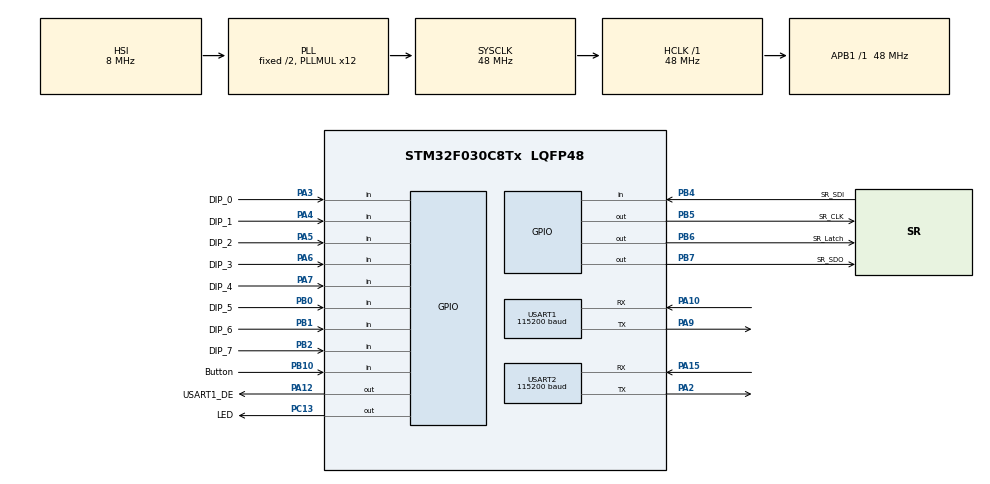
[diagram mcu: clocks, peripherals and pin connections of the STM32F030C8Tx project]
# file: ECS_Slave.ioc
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Mcu.Family=STM32F0
Mcu.Name=STM32F030C8Tx
Mcu.Package=LQFP48
NVIC.USART1_IRQn=true\:0\:0\:false\:false\:true\:true\:true\:true
PA10.Mode=Asynchronous
PA10.Signal=USART1_RX
PA12.GPIO_Label=USART1_DE
PA12.Signal=GPIO_Output
PA13.Mode=Serial_Wire
PA13.Signal=SYS_SWDIO
PA14.Mode=Serial_Wire
PA14.Signal=SYS_SWCLK
PA15.GPIO_PuPd=GPIO_PULLUP
PA15.Mode=Asynchronous
PA15.Signal=USART2_RX
PA2.Mode=Asynchronous
PA2.Signal=USART2_TX
PA3.GPIO_Label=DIP_0
PA3.GPIO_Mode=GPIO_MODE_INPUT
PA3.GPIO_PuPd=GPIO_PULLUP
PA3.Signal=GPIO_Input
PA4.GPIO_Label=DIP_1
PA4.GPIO_Mode=GPIO_MODE_INPUT
PA4.GPIO_PuPd=GPIO_PULLUP
PA4.Signal=GPIO_Input
PA5.GPIO_Label=DIP_2
PA5.GPIO_Mode=GPIO_MODE_INPUT
PA5.GPIO_PuPd=GPIO_PULLUP
PA5.Signal=GPIO_Input
PA6.GPIO_Label=DIP_3
PA6.GPIO_Mode=GPIO_MODE_INPUT
PA6.GPIO_PuPd=GPIO_PULLUP
PA6.Signal=GPIO_Input
PA7.GPIO_Label=DIP_4
PA7.GPIO_Mode=GPIO_MODE_INPUT
PA7.GPIO_PuPd=GPIO_PULLUP
PA7.Signal=GPIO_Input
PA9.Mode=Asynchronous
PA9.Signal=USART1_TX
PB0.GPIO_Label=DIP_5
PB0.GPIO_Mode=GPIO_MODE_INPUT
PB0.GPIO_PuPd=GPIO_PULLUP
PB0.Signal=GPIO_Input
PB1.GPIO_Label=DIP_6
PB1.GPIO_Mode=GPIO_MODE_INPUT
PB1.GPIO_PuPd=GPIO_PULLUP
PB1.Signal=GPIO_Input
PB10.GPIO_Label=Button
PB10.Signal=GPIO_Input
PB2.GPIO_Label=DIP_7
PB2.GPIO_Mode=GPIO_MODE_INPUT
PB2.GPIO_PuPd=GPIO_PULLUP
PB2.Signal=GPIO_Input
PB4.GPIO_Label=SR_SDI
PB4.Signal=GPIO_Input
PB5.GPIO_Label=SR_CLK
PB5.GPIO_Speed=GPIO_SPEED_FREQ_HIGH
PB5.Signal=GPIO_Output
PB6.GPIO_Label=SR_Latch
PB6.GPIO_Speed=GPIO_SPEED_FREQ_HIGH
PB6.PinState=GPIO_PIN_SET
PB6.Signal=GPIO_Output
PB7.GPIO_Label=SR_SDO
PB7.GPIO_Speed=GPIO_SPEED_FREQ_HIGH
PB7.Signal=GPIO_Output
PC13.GPIO_Label=LED
PC13.Signal=GPIO_Output
ProjectManager.HeapSize=0x200
ProjectManager.StackSize=0x400
ProjectManager.TargetToolchain=CMake
RCC.AHBFreq_Value=48000000
RCC.APB1Freq_Value=48000000
RCC.APB1TimFreq_Value=48000000
RCC.HCLKFreq_Value=48000000
RCC.PLLMUL=RCC_PLL_MUL12
RCC.SYSCLKFreq_VALUE=48000000
RCC.SYSCLKSource=RCC_SYSCLKSOURCE_PLLCLK
TIM1.Prescaler=1
USART1.BaudRate=115200
USART1.DMADisableonRxErrorParam=ADVFEATURE_DMA_ENABLEONRXERROR
USART1.OverrunDisableParam=ADVFEATURE_OVERRUN_ENABLE
USART1.VirtualMode-Asynchronous=VM_ASYNC
USART2.BaudRate=115200
USART2.Mode=MODE_TX
USART2.VirtualMode-Asynchronous=VM_ASYNC
VP_TIM1_VS_ClockSourceINT.Mode=Internal
board=custom

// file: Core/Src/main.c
/* USER CODE BEGIN Header */
/**
 ******************************************************************************
 * @file           : main.c
 * @brief          : Main program body
 ******************************************************************************
 * @attention
 *
 * Copyright (c) 2026 STMicroelectronics.
 * All rights reserved.
 *
 * This software is licensed under terms that can be found in the LICENSE file
 * in the root directory of this software component.
 * If no LICENSE file comes with this software, it is provided AS-IS.
 *
 ******************************************************************************
 */
/* USER CODE END Header */
#include "main.h"
#include "tim.h"
#include "usart.h"
#include "gpio.h"

/* USER CODE BEGIN PV */
ModbusInterface_t mb;
/* USER CODE END PV */

void SystemClock_Config(void);

int main(void) {

	/* MCU Configuration--------------------------------------------------------*/

	/* Reset of all peripherals, Initializes the Flash interface and the Systick. */
	HAL_Init();

	/* Configure the system clock */
	SystemClock_Config();

	/* Initialize all configured peripherals */
	MX_GPIO_Init();
	MX_TIM1_Init();
	MX_USART1_UART_Init();
	MX_USART2_UART_Init();
	/* USER CODE BEGIN 2 */
	mb = Modbus_Init(DipSwitch_GetSlaveId());
	hmb = &mb; // Set global pointer for interrupt handlers

	led_init();

	printSplashScreen();

	led_updateMode();
	/* USER CODE END 2 */

	/* Infinite loop */
	while (1) {

		/* USER CODE BEGIN 3 */
		Modbus_Update(&mb);
		led_updateMode();
		HAL_Delay(200);
	}
	/* USER CODE END 3 */
}

void SystemClock_Config(void) {
	RCC_OscInitTypeDef RCC_OscInitStruct = {0};
	RCC_ClkInitTypeDef RCC_ClkInitStruct = {0};
	RCC_PeriphCLKInitTypeDef PeriphClkInit = {0};

	/** Initializes the RCC Oscillators according to the specified parameters
	 * in the RCC_OscInitTypeDef structure.
	 */
	RCC_OscInitStruct.OscillatorType = RCC_OSCILLATORTYPE_HSI;
	RCC_OscInitStruct.HSIState = RCC_HSI_ON;
	RCC_OscInitStruct.HSICalibrationValue = RCC_HSICALIBRATION_DEFAULT;
	RCC_OscInitStruct.PLL.PLLState = RCC_PLL_ON;
	RCC_OscInitStruct.PLL.PLLSource = RCC_PLLSOURCE_HSI;
	RCC_OscInitStruct.PLL.PLLMUL = RCC_PLL_MUL12;
	RCC_OscInitStruct.PLL.PREDIV = RCC_PREDIV_DIV1;
	if (HAL_RCC_OscConfig(&RCC_OscInitStruct) != HAL_OK) {
		Error_Handler();
	}

	/** Initializes the CPU, AHB and APB buses clocks
	 */
	RCC_ClkInitStruct.ClockType = RCC_CLOCKTYPE_HCLK | RCC_CLOCKTYPE_SYSCLK | RCC_CLOCKTYPE_PCLK1;
	RCC_ClkInitStruct.SYSCLKSource = RCC_SYSCLKSOURCE_PLLCLK;
	RCC_ClkInitStruct.AHBCLKDivider = RCC_SYSCLK_DIV1;
	RCC_ClkInitStruct.APB1CLKDivider = RCC_HCLK_DIV1;

	if (HAL_RCC_ClockConfig(&RCC_ClkInitStruct, FLASH_LATENCY_1) != HAL_OK) {
		Error_Handler();
	}
	PeriphClkInit.PeriphClockSelection = RCC_PERIPHCLK_USART1;
	PeriphClkInit.Usart1ClockSelection = RCC_USART1CLKSOURCE_PCLK1;
	if (HAL_RCCEx_PeriphCLKConfig(&PeriphClkInit) != HAL_OK) {
		Error_Handler();
	}
}

void Error_Handler(void) {
	__disable_irq();
	while (1) {
	}
}
#ifdef USE_FULL_ASSERT
/**
 * @brief  Reports the name of the source file and the source line number
 *         where the assert_param error has occurred.
 * @param  file: pointer to the source file name
 * @param  line: assert_param error line source number
 * @retval None
 */
void assert_failed(uint8_t *file, uint32_t line) {
	/* USER CODE BEGIN 6 */
	/* User can add his own implementation to report the file name and line
	   number, ex: printf("Wrong parameters value: file %s on line %d\r\n", file,
	   line) */
	/* USER CODE END 6 */
}
#endif /* USE_FULL_ASSERT */
